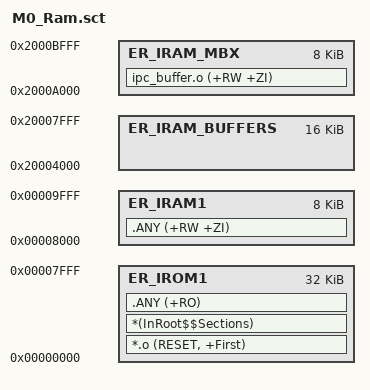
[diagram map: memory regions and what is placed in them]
; *************************************************************
; *** Scatter-Loading Description File generated by uVision ***
; *************************************************************

; memory map assignment
; check with memory_placement.h header
LR_IROM1 0x0  0x8000  {    ; load region size_region

  	; 0x10080000 - 0x10080000
	ER_IROM1 0x0 0x8000  {  ; 32K code space
   
   		*.o (RESET, +First)
   		*(InRoot$$Sections)		   ; only needed if arm library included
   		.ANY (+RO)
	}

  	; 0x10088000 - 0x1008A000
	ER_IRAM1 0x8000 	0x2000 { ; 8 K data space
   		.ANY (+RW +ZI)
	}

   	ER_IRAM_BUFFERS 0x20004000 	0x4000 {
		; empty 
	}


	ER_IRAM_MBX 0x2000A000 0x2000 {
   		ipc_buffer.o (+RW +ZI) 	; hold the mailbox system	
	}
}







